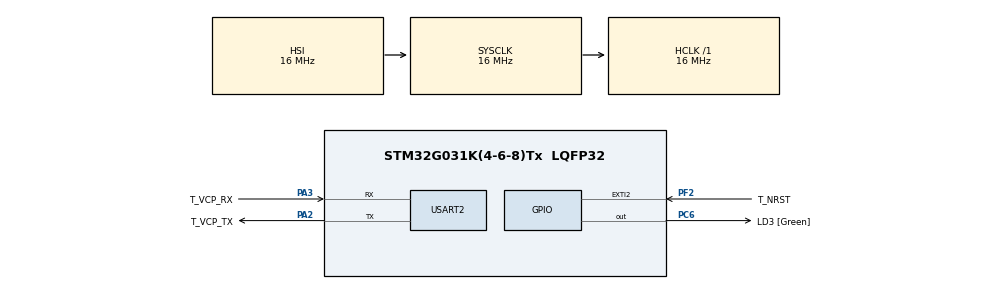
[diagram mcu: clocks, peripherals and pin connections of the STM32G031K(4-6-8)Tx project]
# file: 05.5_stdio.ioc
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Mcu.Family=STM32G0
Mcu.Name=STM32G031K(4-6-8)Tx
Mcu.Package=LQFP32
PA13.GPIO_Label=T_JTMS
PA13.Mode=Serial_Wire
PA13.Signal=SYS_SWDIO
PA14-BOOT0.GPIO_Label=T_JTCK
PA14-BOOT0.Mode=Serial_Wire
PA14-BOOT0.Signal=SYS_SWCLK
PA2.GPIO_Label=T_VCP_TX
PA2.GPIO_PuPd=GPIO_PULLUP
PA2.Mode=Asynchronous
PA2.Signal=USART2_TX
PA3.GPIO_Label=T_VCP_RX
PA3.GPIO_PuPd=GPIO_PULLUP
PA3.Mode=Asynchronous
PA3.Signal=USART2_RX
PC14-OSC32_IN\ (PC14).Mode=LSE-External-Oscillator
PC14-OSC32_IN\ (PC14).Signal=RCC_OSC32_IN
PC15-OSC32_OUT\ (PC15).Mode=LSE-External-Oscillator
PC15-OSC32_OUT\ (PC15).Signal=RCC_OSC32_OUT
PC6.GPIO_Label=LD3 [Green]
PC6.Signal=GPIO_Output
PF2\ -\ NRST.GPIO_Label=T_NRST
PF2\ -\ NRST.Signal=GPXTI2
ProjectManager.HeapSize=0x200
ProjectManager.StackSize=0x400
ProjectManager.TargetToolchain=STM32CubeIDE
RCC.AHBFreq_Value=16000000
RCC.CortexFreq_Value=16000000
RCC.EXTERNAL_CLOCK_VALUE=12288000
RCC.HCLKFreq_Value=16000000
RCC.HSE_VALUE=8000000
RCC.HSI_VALUE=16000000
RCC.SYSCLKFreq_VALUE=16000000
RCC.VCOOutputFreq_Value=128000000
USART2.VirtualMode-Asynchronous=VM_ASYNC
USART2.WordLength=WORDLENGTH_8B
board=NUCLEO-G031K8

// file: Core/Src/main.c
/* USER CODE BEGIN Header */
/**
  ******************************************************************************
  * @file           : main.c
  * @brief          : Main program body
  ******************************************************************************
  * @attention
  *
  * Copyright (c) 2023 STMicroelectronics.
  * All rights reserved.
  *
  * This software is licensed under terms that can be found in the LICENSE file
  * in the root directory of this software component.
  * If no LICENSE file comes with this software, it is provided AS-IS.
  *
  ******************************************************************************
  */
/* USER CODE END Header */
#include "main.h"
#include "usart.h"
#include "gpio.h"

/* USER CODE BEGIN Includes */
#include <stdio.h>				// printf()를 사용하기 위해
#include "seh_stdio.h"
/* USER CODE END Includes */

void SystemClock_Config(void);

int main(void)
{
  /* USER CODE BEGIN 1 */
  int cnt = 0;
  /* USER CODE END 1 */

  /* MCU Configuration--------------------------------------------------------*/

  /* Reset of all peripherals, Initializes the Flash interface and the Systick. */
  HAL_Init();

  /* Configure the system clock */
  SystemClock_Config();

  /* Initialize all configured peripherals */
  MX_GPIO_Init();
  MX_USART2_UART_Init();
  /* USER CODE BEGIN 2 */
  seh_stdio_init(&huart2);				// stdio 초기화.

  /* USER CODE END 2 */

  /* Infinite loop */
  /* USER CODE BEGIN WHILE */
  while (1)
  {
	printf("Hello, CNT=%d\n", cnt++);
	HAL_Delay(100);

    /* USER CODE END WHILE */

  }
}

void SystemClock_Config(void)
{
  RCC_OscInitTypeDef RCC_OscInitStruct = {0};
  RCC_ClkInitTypeDef RCC_ClkInitStruct = {0};

  /** Configure the main internal regulator output voltage
  */
  HAL_PWREx_ControlVoltageScaling(PWR_REGULATOR_VOLTAGE_SCALE1);

  /** Initializes the RCC Oscillators according to the specified parameters
  * in the RCC_OscInitTypeDef structure.
  */
  RCC_OscInitStruct.OscillatorType = RCC_OSCILLATORTYPE_HSI;
  RCC_OscInitStruct.HSIState = RCC_HSI_ON;
  RCC_OscInitStruct.HSIDiv = RCC_HSI_DIV1;
  RCC_OscInitStruct.HSICalibrationValue = RCC_HSICALIBRATION_DEFAULT;
  RCC_OscInitStruct.PLL.PLLState = RCC_PLL_NONE;
  if (HAL_RCC_OscConfig(&RCC_OscInitStruct) != HAL_OK)
  {
    Error_Handler();
  }

  /** Initializes the CPU, AHB and APB buses clocks
  */
  RCC_ClkInitStruct.ClockType = RCC_CLOCKTYPE_HCLK|RCC_CLOCKTYPE_SYSCLK
                              |RCC_CLOCKTYPE_PCLK1;
  RCC_ClkInitStruct.SYSCLKSource = RCC_SYSCLKSOURCE_HSI;
  RCC_ClkInitStruct.AHBCLKDivider = RCC_SYSCLK_DIV1;
  RCC_ClkInitStruct.APB1CLKDivider = RCC_HCLK_DIV1;

  if (HAL_RCC_ClockConfig(&RCC_ClkInitStruct, FLASH_LATENCY_0) != HAL_OK)
  {
    Error_Handler();
  }
}

void Error_Handler(void)
{
  __disable_irq();
  while (1)
  {
  }
}
